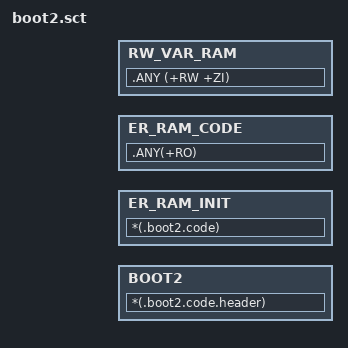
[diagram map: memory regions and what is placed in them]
#! armclang --target=arm-arm-none-eabi -mcpu=cortex-m33 -E -x c

#include "..\config\app_cfg.h"


LOAD_RAM RAM_2ND_BOOT_ADDR RAM_2ND_BOOT_SIZE_MAX
{
    BOOT2 +0
    {
        *(.boot2.code.header)
    }

    ER_RAM_INIT +0
    {
        *(.boot2.code)
    }

    ER_RAM_CODE +0
    {
        .ANY(+RO)
    }

    RW_VAR_RAM +0;
    {
        .ANY (+RW +ZI)
    }
}

